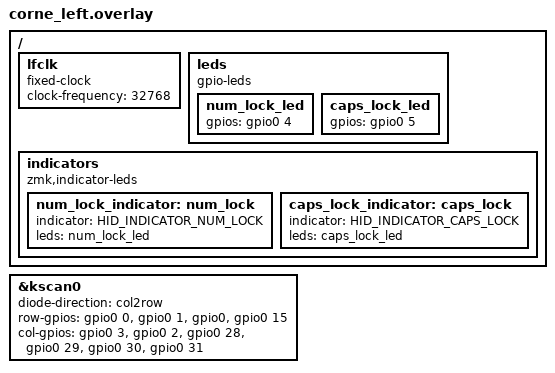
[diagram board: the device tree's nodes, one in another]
/*
 * Copyright (c) 2020 Pete Johanson
 *
 * SPDX-License-Identifier: MIT
 */

#include "corne.dtsi"
#include <dt-bindings/zmk/hid_indicators.h>
&kscan0 {
     diode-direction = "col2row";
    row-gpios
        = <&gpio0  0 (GPIO_ACTIVE_HIGH | GPIO_PULL_DOWN)>
        , <&gpio0  1 (GPIO_ACTIVE_HIGH | GPIO_PULL_DOWN)>
        , <&gpio0  11(GPIO_ACTIVE_HIGH | GPIO_PULL_DOWN)>
        , <&gpio0 15 (GPIO_ACTIVE_HIGH | GPIO_PULL_DOWN)>
        ;

    col-gpios
        = <&gpio0 3 GPIO_ACTIVE_HIGH>
        , <&gpio0 2 GPIO_ACTIVE_HIGH>
        , <&gpio0 28 GPIO_ACTIVE_HIGH>
        , <&gpio0 29 GPIO_ACTIVE_HIGH>
        , <&gpio0 30 GPIO_ACTIVE_HIGH>
        , <&gpio0 31 GPIO_ACTIVE_HIGH>
        ;
};
/ {
    lfclk: lfclk {
        compatible = "fixed-clock";
        clock-frequency = <32768>;
        #clock-cells = <0>;
        status = "okay";
    };
};

/ {
    leds {
        compatible = "gpio-leds";

        num_lock_led: num_lock_led {
            gpios = <&gpio0 4 GPIO_ACTIVE_HIGH>;
        };

        caps_lock_led: caps_lock_led {
            gpios = <&gpio0 5 GPIO_ACTIVE_HIGH>;
        };
    };

    indicators {
        compatible = "zmk,indicator-leds";

        num_lock_indicator: num_lock {
            indicator = <HID_INDICATOR_NUM_LOCK>;
            leds = <&num_lock_led>;
        };

        caps_lock_indicator: caps_lock {
            indicator = <HID_INDICATOR_CAPS_LOCK>;
            leds = <&caps_lock_led>;
        };
    };
};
